VERSION ""

NS_ :

BS_:

BU_:

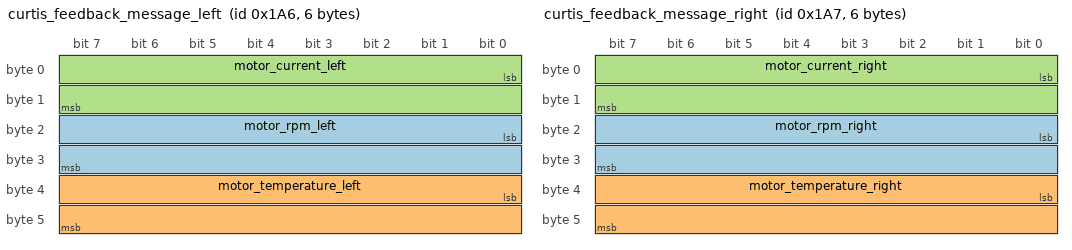
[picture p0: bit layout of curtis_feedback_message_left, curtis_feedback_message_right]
BO_ 422 curtis_feedback_message_left: 6 Vector__XXX
 SG_ motor_rpm_left : 16|16@1- (1,0) [-32768|32767] "rpm" Vector__XXX
 SG_ motor_temperature_left : 32|16@1- (0.1,0) [-100|300] "celsius" Vector__XXX
 SG_ motor_current_left : 0|16@1+ (0.1,0) [0|1000] "A" Vector__XXX

BO_ 423 curtis_feedback_message_right: 6 Vector__XXX
 SG_ motor_rpm_right : 16|16@1- (1,0) [-32768|32767] "rpm" Vector__XXX
 SG_ motor_temperature_right : 32|16@1- (0.1,0) [-100|300] "celsius" Vector__XXX
 SG_ motor_current_right : 0|16@1+ (0.1,0) [0|1000] "A" Vector__XXX

BO_ 550 curtis_input_message_left: 8 Vector__XXX
 SG_ rpm_set_left : 0|16@1- (0.0915527344,0) [-3000|3000] "rpm" Vector__XXX

BO_ 551 curtis_input_message_right: 8 Vector__XXX
 SG_ rpm_set_right : 0|16@1- (0.0915527,0) [-3000|3000] "rpm" Vector__XXX

BO_ 0 curtis_input_operational: 8 Vector__XXX
 SG_ pre_operational : 0|8@1+ (1,0) [0|0] "" Vector__XXX

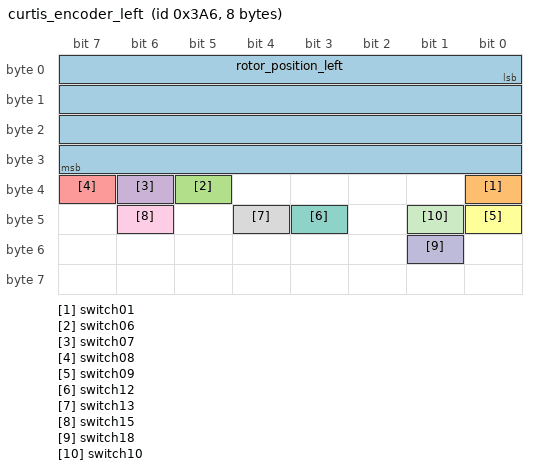
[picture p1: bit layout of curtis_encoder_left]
BO_ 934 curtis_encoder_left: 8 Vector__XXX
 SG_ rotor_position_left : 0|32@1- (1,0) [-2147483648|2147483647] "" Vector__XXX
 SG_ switch01 : 32|1@1+ (1,0) [0|1] "" Vector__XXX
 SG_ switch06 : 37|1@1+ (1,0) [0|1] "" Vector__XXX
 SG_ switch07 : 38|1@1+ (1,0) [0|1] "" Vector__XXX
 SG_ switch08 : 39|1@1+ (1,0) [0|1] "" Vector__XXX
 SG_ switch09 : 40|1@1+ (1,0) [0|1] "" Vector__XXX
 SG_ switch12 : 43|1@1+ (1,0) [0|1] "" Vector__XXX
 SG_ switch13 : 44|1@1+ (1,0) [0|1] "" Vector__XXX
 SG_ switch15 : 46|1@1+ (1,0) [0|1] "" Vector__XXX
 SG_ switch18 : 49|1@1+ (1,0) [0|1] "" Vector__XXX
 SG_ switch10 : 41|1@1+ (1,0) [0|1] "" Vector__XXX

BO_ 935 curtis_encoder_right: 4 Vector__XXX
 SG_ rotor_position_rigth : 0|32@1- (1,0) [-2147483648|2147483647] "" Vector__XXX

BO_ 1830 controller_status_left: 1 Vector__XXX
 SG_ controller_mode_left : 0|8@1+ (1,0) [0|255] "" Vector__XXX

BO_ 1831 controller_status_right: 1 Vector__XXX
 SG_ controller_mode_right : 0|8@1+ (1,0) [0|255] "" Vector__XXX

BO_ 679 curtis_torque_right: 8 Vector__XXX
 SG_ motor_torque_rigth : 0|32@1- (1,0) [-500|500] "Nm" Vector__XXX
 SG_ motor_power_rigth : 32|32@1- (0.1,0) [-100|100] "kW" Vector__XXX

BO_ 678 curtis_torque_left: 8 Vector__XXX
 SG_ motor_torque_left : 0|32@1- (1,0) [-500|500] "Nm" Vector__XXX
 SG_ motor_power_left : 32|32@1- (0.1,0) [-100|100] "kW" Vector__XXX

CM_ BO_ 422 "curtis_feedback_message_left
";
CM_ SG_ 934 switch01 "RCU_FlapLeftFrontUP";
CM_ SG_ 934 switch06 "RCU_FlapRightFrontDown";
CM_ SG_ 934 switch07 "RCU_FlapRightRearUp";
CM_ SG_ 934 switch08 "RCU_FlapLeftRearUp";
CM_ SG_ 934 switch09 "RCU_FlapLeftRearDown";
CM_ SG_ 934 switch12 "atuador_em_posicao";
CM_ SG_ 934 switch13 "RCU_FlapRightFrontUp";
CM_ SG_ 934 switch15 "RCU_FlapLeftFrontDown";
CM_ SG_ 934 switch18 "RCU_FlapRightRearDown";
CM_ SG_ 934 switch10 "mesa_em_posicao";
BA_DEF_  "BusType" STRING ;
BA_DEF_DEF_  "BusType" "CAN";
SIG_VALTYPE_ 679 motor_torque_rigth : 1;
SIG_VALTYPE_ 679 motor_power_rigth : 1;
SIG_VALTYPE_ 678 motor_torque_left : 1;
SIG_VALTYPE_ 678 motor_power_left : 1;
